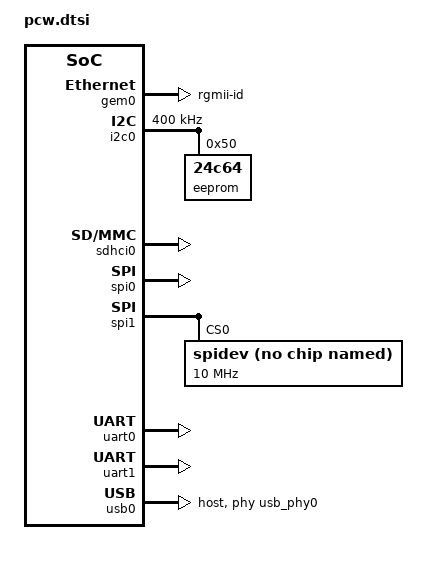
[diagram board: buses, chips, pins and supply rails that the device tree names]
/*
 * CAUTION: This file is automatically generated by Xilinx.
 * Version:  
 * Today is: Thu May  4 13:39:38 2023
 */


/ {
	cpus {
		cpu@0 {
			operating-points = <666666 1000000 333333 1000000>;
		};
	};
};
&gem0 {
	phy-mode = "rgmii-id";
	status = "okay";
	xlnx,ptp-enet-clock = <0x69f6bcb>;
};
&gpio0 {
	emio-gpio-width = <64>;
	gpio-mask-high = <0x0>;
	gpio-mask-low = <0x5600>;
};
&i2c0 {
	clock-frequency = <400000>;
	status = "okay";
};
&i2c0 {
	eeprom@50 {
		compatible = "24c64";
 		size = <8192>;
 		pagesize = <32>;
		reg = <0x50>;
	};
};
&intc {
	num_cpus = <2>;
	num_interrupts = <96>;
};
&sdhci0 {
	status = "okay";
	xlnx,has-cd = <0x1>;
	xlnx,has-power = <0x0>;
	xlnx,has-wp = <0x1>;
};
&spi0 {
	is-decoded-cs = <0>;
	num-cs = <3>;
	status = "okay";
};
&spi1 {
	is-decoded-cs = <0>;
	num-cs = <1>;
	status = "okay";
	spidev@0 {
		compatible = "spidev";
		reg = <0x0>;
		spi-max-frequency = <10000000>;
	};
};
&uart0 {
	cts-override ;
	device_type = "serial";
	port-number = <0>;
	status = "okay";
};
&uart1 {
	cts-override ;
	device_type = "serial";
	port-number = <1>;
	status = "okay";
};
&usb0 {
	dr_mode = "host";
	usb-phy = <&usb_phy0>;
	status = "okay";
	xlnx,phy-reset-gpio = <&gpio0 48 0>;
};
&clkc {
	fclk-enable = <0x0>;
	ps-clk-frequency = <33333333>;
};
&adc {
	xlnx,channels {
		#address-cells = <1>;
		#size-cells = <0>;
		channel@0 {
			reg = <0>;
		};
		channel@1 {
			reg = <1>;
		};
		channel@2 {
			reg = <2>;
		};
		channel@9 {
			reg = <9>;
		};
		channel@10 {
			reg = <10>;
		};
	};
};
